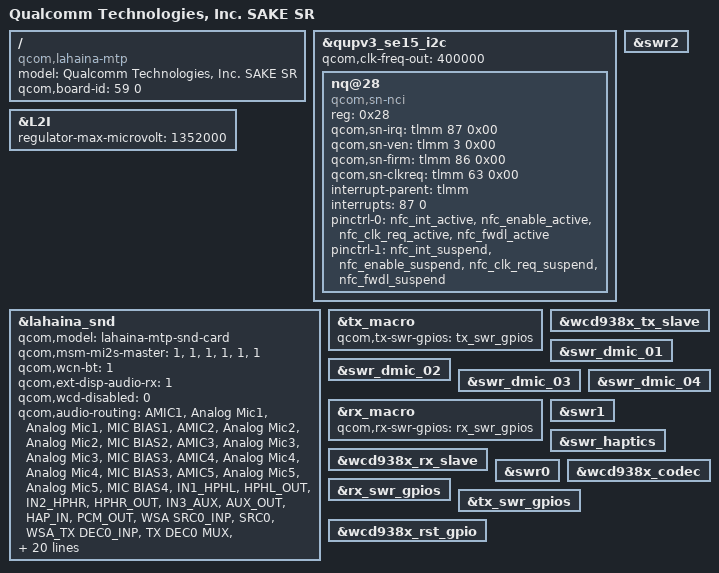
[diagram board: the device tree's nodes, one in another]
/dts-v1/;
/plugin/;

#include "SAKE-EVB2-overlay.dts"
#include "camera/zs590ks-camera-sensor-mtp.dtsi"

/ {
	model = "Qualcomm Technologies, Inc. SAKE SR";
	compatible = "qcom,lahaina-mtp", "qcom,lahaina", "qcom,mtp";
	qcom,board-id = <59 0>;
};

/*   ====================================
*    overlay for display - start
*    ====================================
*/

/*   ====================================
*    overlay for display - end
*    ====================================
*/

/*    ====================================
 *    overlay for lahainap-v2.dtsi - start
 *    ====================================
 */

/*    ====================================
 *    overlay for lahainap-v2.dtsi - end
 *    ====================================
 */



/*    ====================================
 *    overlay for lahainap.dtsi - start
 *    ====================================
 */

/*    ====================================
 *    overlay for lahainap.dtsi - end
 *    ====================================
 */



/*    ====================================
 *    overlay for lahaina-mtp.dtsi - start
 *    ====================================
 */
 
&qupv3_se15_i2c{
	status = "ok";
	qcom,clk-freq-out = <400000>;

	nq@28 {
		compatible = "qcom,sn-nci";
		reg = <0x28>;
		qcom,sn-irq = <&tlmm 87 0x00>;
		qcom,sn-ven = <&tlmm 3 0x00>;
		qcom,sn-firm = <&tlmm 86 0x00>;
		qcom,sn-clkreq = <&tlmm 63 0x00>;
		interrupt-parent = <&tlmm>;
		interrupts = <87 0>;
		interrupt-names = "nfc_irq";
		pinctrl-names = "nfc_active", "nfc_suspend";
		pinctrl-0 = <&nfc_int_active &nfc_enable_active
				&nfc_clk_req_active &nfc_fwdl_active>;
		pinctrl-1 = <&nfc_int_suspend &nfc_enable_suspend
				&nfc_clk_req_suspend &nfc_fwdl_suspend>;
	};
};
 
/*    ====================================
 *    overlay for lahaina-mtp.dtsi - end
 *    ====================================
 */


/*    ====================================
 *    overlay for lahaina-pm.dtsi - start
 *    ====================================
 */

/*    ====================================
 *    overlay for lahaina-pm.dtsi - end
 *    ====================================
 */



/*    ====================================
 *    overlay for lahaina-pinctrl.dtsi - start
 *    ====================================
 */

/*    ====================================
 *    overlay for lahaina-pinctrl.dtsi - end
 *    ====================================
 */



/*    ====================================
 *    overlay for lahaina-pmic-overlay.dtsi - start
 *    ====================================
 */
	&L2I {
		regulator-max-microvolt = <1352000>;
	};

/*    ====================================
 *    overlay for lahaina-pmic-overlay.dtsi - end
 *    ====================================
 */


/*    ====================================
 *    overlay for pm8350.dtsi - start
 *    ====================================
 */

/*    ====================================
 *    overlay for pm8350.dtsi - end
 *    ====================================
 */


/*    ====================================
 *    overlay for pmk8350.dtsi - start
 *    ====================================
 */

/*    ====================================
 *    overlay for pmk8350.dtsi - end
 *    ====================================
 */

/*    ====================================
 *    overlay for pm8350b.dtsi - start
 *    ====================================
 */

/*    ====================================
 *    overlay for pm8350b.dtsi - end
 *    ====================================
 */

/*    ====================================
 *    overlay for pm8350c.dtsi - start
 *    ====================================
 */

/*    ====================================
 *    overlay for pm8350c.dtsi - end
 *    ====================================
 */


/*    ====================================
 *    overlay for lahaina-regulators.dtsi - start
 *    ====================================
 */

/*    ====================================
 *    overlay for lahaina-regulators.dtsi - end
 *    ====================================
 */
  

 
/*    ====================================
 *    overlay for lahaina-audio.dtsi - start
 *    ====================================
 */
 
&lahaina_snd {
	qcom,model = "lahaina-mtp-snd-card";
	qcom,msm-mi2s-master = <1>, <1>, <1>, <1>, <1>, <1>;
	qcom,wcn-bt = <1>;
	qcom,ext-disp-audio-rx = <1>;
	qcom,wcd-disabled = <0>;
	qcom,audio-routing =
		"AMIC1", "Analog Mic1",
		"Analog Mic1", "MIC BIAS1",
		"AMIC2", "Analog Mic2",
		"Analog Mic2", "MIC BIAS2",
		"AMIC3", "Analog Mic3",
		"Analog Mic3", "MIC BIAS3",
		"AMIC4", "Analog Mic4",
		"Analog Mic4", "MIC BIAS3",
		"AMIC5", "Analog Mic5",
		"Analog Mic5", "MIC BIAS4",
		"IN1_HPHL", "HPHL_OUT",
		"IN2_HPHR", "HPHR_OUT",
		"IN3_AUX", "AUX_OUT",
		"HAP_IN", "PCM_OUT",
		"WSA SRC0_INP", "SRC0",
		"WSA_TX DEC0_INP", "TX DEC0 MUX",
		"WSA_TX DEC1_INP", "TX DEC1 MUX",
		"RX_TX DEC0_INP", "TX DEC0 MUX",
		"RX_TX DEC1_INP", "TX DEC1 MUX",
		"RX_TX DEC2_INP", "TX DEC2 MUX",
		"RX_TX DEC3_INP", "TX DEC3 MUX",
		"SpkrLeft IN", "WSA_SPK1 OUT",
		"SpkrRight IN", "WSA_SPK2 OUT",
		"TX SWR_INPUT", "WCD_TX_OUTPUT",
		"VA SWR_INPUT", "VA_SWR_CLK",
		"VA SWR_INPUT", "WCD_TX_OUTPUT",
		"VA_AIF1 CAP", "VA_SWR_CLK",
		"VA_AIF2 CAP", "VA_SWR_CLK",
		"VA_AIF3 CAP", "VA_SWR_CLK";
	qcom,msm-mbhc-hphl-swh = <1>;
	qcom,msm-mbhc-gnd-swh = <1>;
	asoc-codec  = <&stub_codec>, <&bolero>,
		      <&wcd938x_codec>, <&swr_haptics>,
		      <&ext_disp_audio_codec>;
	asoc-codec-names = "msm-stub-codec.1", "bolero_codec",
			   "wcd938x_codec", "swr-haptics",
			   "msm-ext-disp-audio-codec-rx";
	qcom,wsa-max-devs;
	qcom,cdc-dmic45-gpios;
	qcom,msm_audio_ssr_devs = <&audio_apr>, <&q6core>, <&lpi_tlmm>,
				  <&bolero>;
};

&tx_macro {
	qcom,tx-swr-gpios = <&tx_swr_gpios>;
};

&swr2 {
	status = "ok";
};

&wcd938x_tx_slave {
	status = "ok";
};

&swr_dmic_01 {
	status = "ok";
};

&swr_dmic_02 {
	status = "ok";
};

&swr_dmic_03 {
	status = "ok";
};

&swr_dmic_04 {
	status = "ok";
};

&rx_macro {
	qcom,rx-swr-gpios = <&rx_swr_gpios>;
};

&swr1 {
	status = "ok";
};

&swr_haptics {
	status = "ok";
};

&wcd938x_rx_slave {
	status = "ok";
};

&swr0 {
	status = "ok";
};

&wcd938x_codec {
	status = "ok";
};

&rx_swr_gpios {
	status = "ok";
};

&tx_swr_gpios {
	status = "ok";
};

&wcd938x_rst_gpio {
	status = "ok";
};


/*    ====================================
 *    overlay for lahaina-audio.dtsi - end
 *    ====================================
 */

/*    ====================================
 *    overlay for lahaina-audio-overlay.dtsi - start
 *    ====================================
 */

/*    ====================================
 *    overlay for lahaina-audio-overlay.dtsi - end
 *    ====================================
 */


/*    ====================================
 *    overlay for lahaina-thermal-overlay.dtsi - start
 *    ====================================
 */

/*    ====================================
 *    overlay for lahaina-thermal-overlay.dtsi - end
 *    ====================================
 */

 
/*    ====================================
 *    overlay for lahaina-gpu.dtsi - start
 *    ====================================
 */

/*    ====================================
 *    overlay for lahaina-gpu.dtsi - end
 *    ====================================
 */


/*    ====================================
 *    overlay for lahaina-usb.dtsi - start
 *    ====================================
 */

/*    ====================================
 *    overlay for lahaina-usb.dtsi - end
 *    ====================================
 */
 
